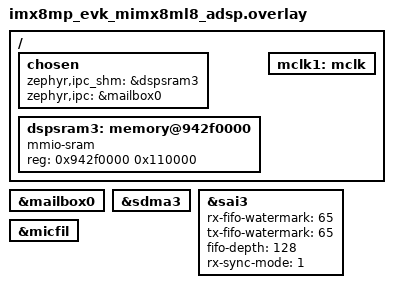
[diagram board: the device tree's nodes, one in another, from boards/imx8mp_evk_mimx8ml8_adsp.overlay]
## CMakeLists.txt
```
# SPDX-License-Identifier: BSD-3-Clause

cmake_minimum_required(VERSION 3.20.0)

find_package(Zephyr REQUIRED HINTS $ENV{ZEPHYR_BASE})
project(sample_are)

add_compile_options(-Wno-dev)

target_sources(app PRIVATE src/main.c)

target_compile_options(app PRIVATE -g)

target_link_libraries(app PUBLIC spf)

# Added to check for alignment error in filesz in zephyr.elf fragments. Do readelf -l zephyr.elf
set(CMAKE_EXE_LINKER_FLAGS "${CMAKE_EXE_LINKER_FLAGS} -Wl,--align-segments=4")

include_directories(
	${ZEPHYR_ARE_MODULE_DIR}/fwk/spf/utils/cmn/inc
	${ZEPHYR_ARE_MODULE_DIR}/fwk/platform/posal/inc
	${ZEPHYR_ARE_MODULE_DIR}/fwk/platform/posal/inc/linux/
	${ZEPHYR_ARE_MODULE_DIR}/fwk/platform/posal/inc/linux/stringl
	${ZEPHYR_ARE_MODULE_DIR}/fwk/api/ar_utils
	${ZEPHYR_ARE_MODULE_DIR}/fwk/api/ar_utils/generic/
	${ZEPHYR_ARE_MODULE_DIR}/ar_osal/api
	${ZEPHYR_ARE_MODULE_DIR}/gpr/api
	${ZEPHYR_HAL_XTENSA_MODULE_DIR}/include
	${ZEPHYR_BASE}/include/zephyr/
	${ZEPHYR_BASE}/include/
	#${ZEPHYR_BASE}/include/zephyr/posix
	${CMAKE_BINARY_DIR}/zephyr/include/generated
  	${CMAKE_BINARY_DIR}/include/generated
	)

zephyr_include_directories()
```

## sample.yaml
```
sample:
  description: Audio with are
  name: are
common:
  tags: audio
  modules:
    - are
```

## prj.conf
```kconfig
CONFIG_PRINTK=n
CONFIG_IPM=y
CONFIG_MAIN_STACK_SIZE=1024
CONFIG_HEAP_MEM_POOL_SIZE=1024
CONFIG_OPENAMP=y
CONFIG_OPENAMP_RSC_TABLE_NUM_RPMSG_BUFF=32
CONFIG_OPENAMP_RSC_TABLE=y
CONFIG_OPENAMP_MASTER=n

CONFIG_SHELL=y
CONFIG_SHELL_BACKEND_RPMSG=y
CONFIG_LOG_DEFAULT_LEVEL=1

CONFIG_DAI=y
CONFIG_DMA=y
CONFIG_DAI_NXP_SAI=y
CONFIG_DMA_NXP_SDMA=y
CONFIG_SAI_HAS_MCLK_CONFIG_OPTION=y
CONFIG_CLOCK_CONTROL_FIXED_RATE_CLOCK=y

#AudioReach Engine specific configs.
CONFIG_POSIX_API=y
CONFIG_POSIX_THREADS=y
CONFIG_POSIX_THREADS_EXT=y
CONFIG_POSIX_SHARED_MEMORY_OBJECTS=y
CONFIG_POSIX_PRIORITY_SCHEDULING=y
CONFIG_POSIX_TIMERS=y
CONFIG_POSIX_MONOTONIC_CLOCK=y
CONFIG_POSIX_THREAD_PRIORITY_SCHEDULING=y
CONFIG_POSIX_THREAD_THREADS_MAX=7
CONFIG_POSIX_THREAD_KEYS_MAX=7
CONFIG_LOG=y
CONFIG_DEBUG_THREAD_INFO=y
CONFIG_THREAD_NAME=y
CONFIG_MAX_PTHREAD_MUTEX_COUNT=70
CONFIG_MAX_PTHREAD_SPINLOCK_COUNT=10
CONFIG_MAX_PTHREAD_COND_COUNT=20
CONFIG_HEAP_MEM_POOL_SIZE=32768
CONFIG_MAIN_STACK_SIZE=32768
CONFIG_IDLE_STACK_SIZE=4096
CONFIG_ISR_STACK_SIZE=4096
CONFIG_DYNAMIC_THREAD=y
CONFIG_DYNAMIC_THREAD_POOL_SIZE=10
CONFIG_DYNAMIC_THREAD_STACK_SIZE=32768
CONFIG_NEWLIB_LIBC=y
CONFIG_LOG_BUFFER_SIZE=16384
CONFIG_LOG_PROCESS_THREAD_STACK_SIZE=16384

CONFIG_SYS_CLOCK_TICKS_PER_SEC=100000
CONFIG_PROC_DOMAIN="ADSP"
CONFIG_ALSA_DEVICE_SINK=n
CONFIG_NXP_DEVICE_SINK=y
CONFIG_LOG_MODE_DEFERRED=y
CONFIG_SHARED_INTERRUPTS=y
#CONFIG_ZEPHYR_NATIVE_DRIVERS=y

# to enable zephyr logging.
CONFIG_LOG_BACKEND_UART=y

#disable modules
CONFIG_DYNAMIC_RESAMPLER=n
CONFIG_IIR_RESAMPLER=n
CONFIG_SH_MEM_PULL_MODE=n
CONFIG_SH_MEM_PUSH_MODE=n
CONFIG_LATENCY=n
CONFIG_SYNC=n
CONFIG_SPR=n
CONFIG_SPLITTER=n
CONFIG_DATA_MARKER=n
CONFIG_PRIORITY_SYNC=n
CONFIG_MUX_DEMUX=n
CONFIG_ECHO_CANCELLATION=n
CONFIG_ENCODER=n
CONFIG_CHMIXER=n
CONFIG_PCM_CNV=n

# Additional Configuration.
CONFIG_IRM=n
```

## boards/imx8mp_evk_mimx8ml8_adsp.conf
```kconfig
CONFIG_LOG_PRINTK=n
CONFIG_IPM_IMX_MAX_DATA_SIZE_16=n
CONFIG_IPM_IMX_MAX_DATA_SIZE_4=y
CONFIG_OPENAMP_WITH_DCACHE=y
CONFIG_IPM_IMX_FW_READY_REPLY=y
CONFIG_DAI=y
CONFIG_DMA=y
CONFIG_DAI_NXP_SAI=y
CONFIG_DMA_NXP_SDMA=y
CONFIG_SAI_HAS_MCLK_CONFIG_OPTION=y
CONFIG_CLOCK_CONTROL_FIXED_RATE_CLOCK=y
```

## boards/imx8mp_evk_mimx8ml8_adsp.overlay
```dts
/*
 * Copyright (c) 2023 NXP
 *
 * SPDX-License-Identifier: Apache-2.0
 */

/ {
	chosen {
		/*
		 * shared memory reserved for the inter-processor communication
		 */
		zephyr,ipc_shm = &dspsram3;
		zephyr,ipc = &mailbox0;
	};

	dspsram3: memory@942f0000 {
		compatible = "mmio-sram";
		reg = <0x942f0000 0x110000>;
	};
	
	mclk1: mclk {
		status = "okay"; 
	};
	
};

&mailbox0 {
	status = "okay";
};

&sdma3 {
	status = "okay";
};

&sai3 {
	rx-fifo-watermark = <65>;
	tx-fifo-watermark = <65>;
	fifo-depth = <128>;
	rx-sync-mode = <1>;
	status = "okay";
};

&micfil {
	status = "okay";
};
```

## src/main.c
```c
/*
 * Copyright (c) Qualcomm Technologies, Inc. and/or its subsidiaries.
 * SPDX-License-Identifier: BSD-3-Clause
 */

#include <stdio.h>
#include <posal.h>
#include "posal.h"
#include <spf_main.h>
#include <gpr_api.h>

int main(void)
{
    int rc = 0;
    posal_init();
	
    rc = gpr_init();
    if (0 != rc) {
	    printf("gpr_init() failed with status %d\n", rc);
        return rc;
    }
	
    rc = spf_framework_pre_init();
    if (0 != rc) {
	    printf("spf_framework_pre_init() failed with status %d\n", rc);
        return rc;
    }
	
    rc = spf_framework_post_init();
    if (0 != rc) {
		printf("spf_framework_post_init() failed with status %d\n", rc);
        return rc;
    }

	printf("spf framework initialized.\n", rc);

	/*apm_test_launch();
	printf("after apm_test_launch() \n");


	spf_framework_pre_deinit();
	printf("after  spf_framework_pre_deinit call\n");

    spf_framework_post_deinit();
	printf("after  spf_framework_post_deinit call\n");
	
	printf("before gpr_deinit call\n");
	gpr_deinit();
	printf("after gpr_deinit call\n");
	
	posal_deinit();
	printf("After posal deinit call\n");*/
	    
    return 0;
}
```
